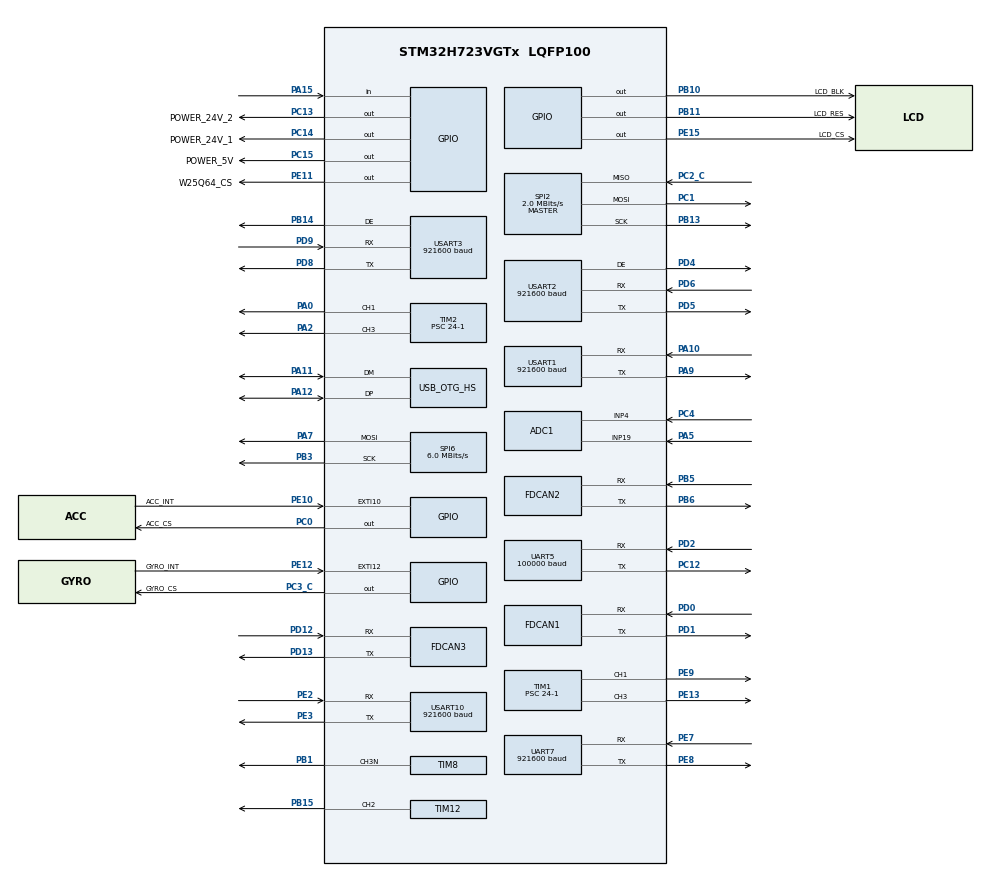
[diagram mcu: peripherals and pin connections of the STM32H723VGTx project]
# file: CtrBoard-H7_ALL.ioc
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ADC1.Channel-0\#ChannelRegularConversion=ADC_CHANNEL_4
ADC1.Channel-1\#ChannelRegularConversion=ADC_CHANNEL_19
ADC1.ClockPrescaler=ADC_CLOCK_ASYNC_DIV64
ADC1.ContinuousConvMode=ENABLE
ADC1.ConversionDataManagement=ADC_CONVERSIONDATA_DMA_CIRCULAR
ADC1.NbrOfConversion=2
ADC1.NbrOfConversionFlag=1
ADC1.OffsetNumber-0\#ChannelRegularConversion=ADC_OFFSET_NONE
ADC1.OffsetNumber-1\#ChannelRegularConversion=ADC_OFFSET_NONE
ADC1.OffsetSignedSaturation-0\#ChannelRegularConversion=DISABLE
ADC1.OffsetSignedSaturation-1\#ChannelRegularConversion=DISABLE
ADC1.Rank-0\#ChannelRegularConversion=1
ADC1.Rank-1\#ChannelRegularConversion=2
ADC1.SamplingTime-0\#ChannelRegularConversion=ADC_SAMPLETIME_32CYCLES_5
ADC1.SamplingTime-1\#ChannelRegularConversion=ADC_SAMPLETIME_32CYCLES_5
ADC1.master=1
Bdma.Request0=SPI6_TX
Bdma.RequestsNb=1
Bdma.SPI6_TX.0.Direction=DMA_MEMORY_TO_PERIPH
Bdma.SPI6_TX.0.EventEnable=DISABLE
Bdma.SPI6_TX.0.Instance=BDMA_Channel0
Bdma.SPI6_TX.0.MemDataAlignment=DMA_MDATAALIGN_BYTE
Bdma.SPI6_TX.0.MemInc=DMA_MINC_ENABLE
Bdma.SPI6_TX.0.Mode=DMA_NORMAL
Bdma.SPI6_TX.0.PeriphDataAlignment=DMA_PDATAALIGN_BYTE
Bdma.SPI6_TX.0.PeriphInc=DMA_PINC_DISABLE
Bdma.SPI6_TX.0.Polarity=HAL_DMAMUX_REQ_GEN_RISING
Bdma.SPI6_TX.0.Priority=DMA_PRIORITY_LOW
Bdma.SPI6_TX.0.RequestNumber=1
Bdma.SPI6_TX.0.SignalID=NONE
Bdma.SPI6_TX.0.SyncEnable=DISABLE
Bdma.SPI6_TX.0.SyncPolarity=HAL_DMAMUX_SYNC_NO_EVENT
Bdma.SPI6_TX.0.SyncRequestNumber=1
Bdma.SPI6_TX.0.SyncSignalID=NONE
CORTEX_M7.CPU_DCache=Enabled
CORTEX_M7.CPU_ICache=Enabled
CORTEX_M7.Enable-Cortex_Memory_Protection_Unit_Region0_Settings=MPU_REGION_ENABLE
CORTEX_M7.MPU_Control=__NULL
CORTEX_M7.default_mode_Activation=1
DAC1.DAC_Channel-DAC_OUT2_Int=DAC_CHANNEL_2
Dma.ADC1.0.Direction=DMA_PERIPH_TO_MEMORY
Dma.ADC1.0.EventEnable=DISABLE
Dma.ADC1.0.FIFOMode=DMA_FIFOMODE_DISABLE
Dma.ADC1.0.Instance=DMA1_Stream0
Dma.ADC1.0.MemDataAlignment=DMA_MDATAALIGN_HALFWORD
Dma.ADC1.0.MemInc=DMA_MINC_ENABLE
Dma.ADC1.0.Mode=DMA_CIRCULAR
Dma.ADC1.0.PeriphDataAlignment=DMA_PDATAALIGN_HALFWORD
Dma.ADC1.0.PeriphInc=DMA_PINC_DISABLE
Dma.ADC1.0.Polarity=HAL_DMAMUX_REQ_GEN_RISING
Dma.ADC1.0.Priority=DMA_PRIORITY_LOW
Dma.ADC1.0.RequestNumber=1
Dma.ADC1.0.SignalID=NONE
Dma.ADC1.0.SyncEnable=DISABLE
Dma.ADC1.0.SyncPolarity=HAL_DMAMUX_SYNC_NO_EVENT
Dma.ADC1.0.SyncRequestNumber=1
Dma.ADC1.0.SyncSignalID=NONE
Dma.Request0=ADC1
Dma.Request1=SPI2_RX
Dma.Request10=USART3_TX
Dma.Request11=USART10_RX
Dma.Request12=USART10_TX
Dma.Request13=UART5_RX
Dma.Request2=SPI2_TX
Dma.Request3=UART7_RX
Dma.Request4=UART7_TX
Dma.Request5=USART1_RX
Dma.Request6=USART1_TX
Dma.Request7=USART2_RX
Dma.Request8=USART2_TX
Dma.Request9=USART3_RX
Dma.SPI2_RX.1.Direction=DMA_PERIPH_TO_MEMORY
Dma.SPI2_RX.1.EventEnable=DISABLE
Dma.SPI2_RX.1.FIFOMode=DMA_FIFOMODE_DISABLE
Dma.SPI2_RX.1.Instance=DMA1_Stream2
Dma.SPI2_RX.1.MemDataAlignment=DMA_MDATAALIGN_BYTE
Dma.SPI2_RX.1.MemInc=DMA_MINC_ENABLE
Dma.SPI2_RX.1.Mode=DMA_NORMAL
Dma.SPI2_RX.1.PeriphDataAlignment=DMA_PDATAALIGN_BYTE
Dma.SPI2_RX.1.PeriphInc=DMA_PINC_DISABLE
Dma.SPI2_RX.1.Polarity=HAL_DMAMUX_REQ_GEN_RISING
Dma.SPI2_RX.1.Priority=DMA_PRIORITY_LOW
Dma.SPI2_RX.1.RequestNumber=1
Dma.SPI2_RX.1.SignalID=NONE
Dma.SPI2_RX.1.SyncEnable=DISABLE
Dma.SPI2_RX.1.SyncPolarity=HAL_DMAMUX_SYNC_NO_EVENT
Dma.SPI2_RX.1.SyncRequestNumber=1
Dma.SPI2_RX.1.SyncSignalID=NONE
Dma.SPI2_TX.2.Direction=DMA_MEMORY_TO_PERIPH
Dma.SPI2_TX.2.EventEnable=DISABLE
Dma.SPI2_TX.2.FIFOMode=DMA_FIFOMODE_DISABLE
Dma.SPI2_TX.2.Instance=DMA1_Stream3
Dma.SPI2_TX.2.MemDataAlignment=DMA_MDATAALIGN_BYTE
Dma.SPI2_TX.2.MemInc=DMA_MINC_ENABLE
Dma.SPI2_TX.2.Mode=DMA_NORMAL
Dma.SPI2_TX.2.PeriphDataAlignment=DMA_PDATAALIGN_BYTE
Dma.SPI2_TX.2.PeriphInc=DMA_PINC_DISABLE
Dma.SPI2_TX.2.Polarity=HAL_DMAMUX_REQ_GEN_RISING
Dma.SPI2_TX.2.Priority=DMA_PRIORITY_LOW
Dma.SPI2_TX.2.RequestNumber=1
Dma.SPI2_TX.2.SignalID=NONE
Dma.SPI2_TX.2.SyncEnable=DISABLE
Dma.SPI2_TX.2.SyncPolarity=HAL_DMAMUX_SYNC_NO_EVENT
Dma.SPI2_TX.2.SyncRequestNumber=1
Dma.SPI2_TX.2.SyncSignalID=NONE
Dma.UART5_RX.13.Direction=DMA_PERIPH_TO_MEMORY
Dma.UART5_RX.13.EventEnable=DISABLE
Dma.UART5_RX.13.FIFOMode=DMA_FIFOMODE_DISABLE
Dma.UART5_RX.13.Instance=DMA1_Stream1
Dma.UART5_RX.13.MemDataAlignment=DMA_MDATAALIGN_BYTE
Dma.UART5_RX.13.MemInc=DMA_MINC_ENABLE
Dma.UART5_RX.13.Mode=DMA_NORMAL
Dma.UART5_RX.13.PeriphDataAlignment=DMA_PDATAALIGN_BYTE
Dma.UART5_RX.13.PeriphInc=DMA_PINC_DISABLE
Dma.UART5_RX.13.Polarity=HAL_DMAMUX_REQ_GEN_RISING
Dma.UART5_RX.13.Priority=DMA_PRIORITY_LOW
Dma.UART5_RX.13.RequestNumber=1
Dma.UART5_RX.13.SignalID=NONE
Dma.UART5_RX.13.SyncEnable=DISABLE
Dma.UART5_RX.13.SyncPolarity=HAL_DMAMUX_SYNC_NO_EVENT
Dma.UART5_RX.13.SyncRequestNumber=1
Dma.UART5_RX.13.SyncSignalID=NONE
Dma.UART7_RX.3.Direction=DMA_PERIPH_TO_MEMORY
Dma.UART7_RX.3.EventEnable=DISABLE
Dma.UART7_RX.3.FIFOMode=DMA_FIFOMODE_DISABLE
Dma.UART7_RX.3.Instance=DMA1_Stream4
Dma.UART7_RX.3.MemDataAlignment=DMA_MDATAALIGN_BYTE
Dma.UART7_RX.3.MemInc=DMA_MINC_ENABLE
Dma.UART7_RX.3.Mode=DMA_NORMAL
Dma.UART7_RX.3.PeriphDataAlignment=DMA_PDATAALIGN_BYTE
Dma.UART7_RX.3.PeriphInc=DMA_PINC_DISABLE
Dma.UART7_RX.3.Polarity=HAL_DMAMUX_REQ_GEN_RISING
Dma.UART7_RX.3.Priority=DMA_PRIORITY_LOW
Dma.UART7_RX.3.RequestNumber=1
Dma.UART7_RX.3.SignalID=NONE
Dma.UART7_RX.3.SyncEnable=DISABLE
Dma.UART7_RX.3.SyncPolarity=HAL_DMAMUX_SYNC_NO_EVENT
Dma.UART7_RX.3.SyncRequestNumber=1
Dma.UART7_RX.3.SyncSignalID=NONE
Dma.UART7_TX.4.Direction=DMA_MEMORY_TO_PERIPH
Dma.UART7_TX.4.EventEnable=DISABLE
Dma.UART7_TX.4.FIFOMode=DMA_FIFOMODE_DISABLE
Dma.UART7_TX.4.Instance=DMA1_Stream5
Dma.UART7_TX.4.MemDataAlignment=DMA_MDATAALIGN_BYTE
Dma.UART7_TX.4.MemInc=DMA_MINC_ENABLE
Dma.UART7_TX.4.Mode=DMA_NORMAL
Dma.UART7_TX.4.PeriphDataAlignment=DMA_PDATAALIGN_BYTE
Dma.UART7_TX.4.PeriphInc=DMA_PINC_DISABLE
Dma.UART7_TX.4.Polarity=HAL_DMAMUX_REQ_GEN_RISING
Dma.UART7_TX.4.Priority=DMA_PRIORITY_LOW
Dma.UART7_TX.4.RequestNumber=1
Dma.UART7_TX.4.SignalID=NONE
Dma.UART7_TX.4.SyncEnable=DISABLE
Dma.UART7_TX.4.SyncPolarity=HAL_DMAMUX_SYNC_NO_EVENT
Dma.UART7_TX.4.SyncRequestNumber=1
Dma.UART7_TX.4.SyncSignalID=NONE
Dma.USART10_RX.11.Direction=DMA_PERIPH_TO_MEMORY
Dma.USART10_RX.11.EventEnable=DISABLE
Dma.USART10_RX.11.FIFOMode=DMA_FIFOMODE_DISABLE
Dma.USART10_RX.11.Instance=DMA2_Stream4
Dma.USART10_RX.11.MemDataAlignment=DMA_MDATAALIGN_BYTE
Dma.USART10_RX.11.MemInc=DMA_MINC_ENABLE
Dma.USART10_RX.11.Mode=DMA_NORMAL
Dma.USART10_RX.11.PeriphDataAlignment=DMA_PDATAALIGN_BYTE
Dma.USART10_RX.11.PeriphInc=DMA_PINC_DISABLE
Dma.USART10_RX.11.Polarity=HAL_DMAMUX_REQ_GEN_RISING
Dma.USART10_RX.11.Priority=DMA_PRIORITY_LOW
Dma.USART10_RX.11.RequestNumber=1
Dma.USART10_RX.11.SignalID=NONE
Dma.USART10_RX.11.SyncEnable=DISABLE
Dma.USART10_RX.11.SyncPolarity=HAL_DMAMUX_SYNC_NO_EVENT
Dma.USART10_RX.11.SyncRequestNumber=1
Dma.USART10_RX.11.SyncSignalID=NONE
Dma.USART10_TX.12.Direction=DMA_MEMORY_TO_PERIPH
Dma.USART10_TX.12.EventEnable=DISABLE
Dma.USART10_TX.12.FIFOMode=DMA_FIFOMODE_DISABLE
Dma.USART10_TX.12.Instance=DMA2_Stream5
Dma.USART10_TX.12.MemDataAlignment=DMA_MDATAALIGN_BYTE
Dma.USART10_TX.12.MemInc=DMA_MINC_ENABLE
Dma.USART10_TX.12.Mode=DMA_NORMAL
Dma.USART10_TX.12.PeriphDataAlignment=DMA_PDATAALIGN_BYTE
Dma.USART10_TX.12.PeriphInc=DMA_PINC_DISABLE
Dma.USART10_TX.12.Polarity=HAL_DMAMUX_REQ_GEN_RISING
Dma.USART10_TX.12.Priority=DMA_PRIORITY_LOW
Dma.USART10_TX.12.RequestNumber=1
Dma.USART10_TX.12.SignalID=NONE
Dma.USART10_TX.12.SyncEnable=DISABLE
Dma.USART10_TX.12.SyncPolarity=HAL_DMAMUX_SYNC_NO_EVENT
Dma.USART10_TX.12.SyncRequestNumber=1
Dma.USART10_TX.12.SyncSignalID=NONE
Dma.USART1_RX.5.Direction=DMA_PERIPH_TO_MEMORY
Dma.USART1_RX.5.EventEnable=DISABLE
Dma.USART1_RX.5.FIFOMode=DMA_FIFOMODE_DISABLE
Dma.USART1_RX.5.Instance=DMA1_Stream6
Dma.USART1_RX.5.MemDataAlignment=DMA_MDATAALIGN_BYTE
Dma.USART1_RX.5.MemInc=DMA_MINC_ENABLE
Dma.USART1_RX.5.Mode=DMA_NORMAL
Dma.USART1_RX.5.PeriphDataAlignment=DMA_PDATAALIGN_BYTE
Dma.USART1_RX.5.PeriphInc=DMA_PINC_DISABLE
Dma.USART1_RX.5.Polarity=HAL_DMAMUX_REQ_GEN_RISING
Dma.USART1_RX.5.Priority=DMA_PRIORITY_LOW
Dma.USART1_RX.5.RequestNumber=1
Dma.USART1_RX.5.SignalID=NONE
Dma.USART1_RX.5.SyncEnable=DISABLE
Dma.USART1_RX.5.SyncPolarity=HAL_DMAMUX_SYNC_NO_EVENT
Dma.USART1_RX.5.SyncRequestNumber=1
Dma.USART1_RX.5.SyncSignalID=NONE
Dma.USART1_TX.6.Direction=DMA_MEMORY_TO_PERIPH
Dma.USART1_TX.6.EventEnable=DISABLE
Dma.USART1_TX.6.FIFOMode=DMA_FIFOMODE_DISABLE
Dma.USART1_TX.6.Instance=DMA1_Stream7
Dma.USART1_TX.6.MemDataAlignment=DMA_MDATAALIGN_BYTE
Dma.USART1_TX.6.MemInc=DMA_MINC_ENABLE
Dma.USART1_TX.6.Mode=DMA_NORMAL
Dma.USART1_TX.6.PeriphDataAlignment=DMA_PDATAALIGN_BYTE
Dma.USART1_TX.6.PeriphInc=DMA_PINC_DISABLE
Dma.USART1_TX.6.Polarity=HAL_DMAMUX_REQ_GEN_RISING
Dma.USART1_TX.6.Priority=DMA_PRIORITY_LOW
Dma.USART1_TX.6.RequestNumber=1
Dma.USART1_TX.6.SignalID=NONE
Dma.USART1_TX.6.SyncEnable=DISABLE
Dma.USART1_TX.6.SyncPolarity=HAL_DMAMUX_SYNC_NO_EVENT
Dma.USART1_TX.6.SyncRequestNumber=1
Dma.USART1_TX.6.SyncSignalID=NONE
Dma.USART2_RX.7.Direction=DMA_PERIPH_TO_MEMORY
Dma.USART2_RX.7.EventEnable=DISABLE
Dma.USART2_RX.7.FIFOMode=DMA_FIFOMODE_DISABLE
Dma.USART2_RX.7.Instance=DMA2_Stream0
Dma.USART2_RX.7.MemDataAlignment=DMA_MDATAALIGN_BYTE
Dma.USART2_RX.7.MemInc=DMA_MINC_ENABLE
Dma.USART2_RX.7.Mode=DMA_NORMAL
Dma.USART2_RX.7.PeriphDataAlignment=DMA_PDATAALIGN_BYTE
Dma.USART2_RX.7.PeriphInc=DMA_PINC_DISABLE
Dma.USART2_RX.7.Polarity=HAL_DMAMUX_REQ_GEN_RISING
Dma.USART2_RX.7.Priority=DMA_PRIORITY_LOW
Dma.USART2_RX.7.RequestNumber=1
Dma.USART2_RX.7.SignalID=NONE
Dma.USART2_RX.7.SyncEnable=DISABLE
Dma.USART2_RX.7.SyncPolarity=HAL_DMAMUX_SYNC_NO_EVENT
Dma.USART2_RX.7.SyncRequestNumber=1
Dma.USART2_RX.7.SyncSignalID=NONE
Dma.USART2_TX.8.Direction=DMA_MEMORY_TO_PERIPH
Dma.USART2_TX.8.EventEnable=DISABLE
Dma.USART2_TX.8.FIFOMode=DMA_FIFOMODE_DISABLE
Dma.USART2_TX.8.Instance=DMA2_Stream1
Dma.USART2_TX.8.MemDataAlignment=DMA_MDATAALIGN_BYTE
Dma.USART2_TX.8.MemInc=DMA_MINC_ENABLE
Dma.USART2_TX.8.Mode=DMA_NORMAL
Dma.USART2_TX.8.PeriphDataAlignment=DMA_PDATAALIGN_BYTE
Dma.USART2_TX.8.PeriphInc=DMA_PINC_DISABLE
Dma.USART2_TX.8.Polarity=HAL_DMAMUX_REQ_GEN_RISING
Dma.USART2_TX.8.Priority=DMA_PRIORITY_LOW
Dma.USART2_TX.8.RequestNumber=1
Dma.USART2_TX.8.SignalID=NONE
Dma.USART2_TX.8.SyncEnable=DISABLE
Dma.USART2_TX.8.SyncPolarity=HAL_DMAMUX_SYNC_NO_EVENT
Dma.USART2_TX.8.SyncRequestNumber=1
Dma.USART2_TX.8.SyncSignalID=NONE
Dma.USART3_RX.9.Direction=DMA_PERIPH_TO_MEMORY
Dma.USART3_RX.9.EventEnable=DISABLE
Dma.USART3_RX.9.FIFOMode=DMA_FIFOMODE_DISABLE
Dma.USART3_RX.9.Instance=DMA2_Stream2
Dma.USART3_RX.9.MemDataAlignment=DMA_MDATAALIGN_BYTE
Dma.USART3_RX.9.MemInc=DMA_MINC_ENABLE
Dma.USART3_RX.9.Mode=DMA_NORMAL
Dma.USART3_RX.9.PeriphDataAlignment=DMA_PDATAALIGN_BYTE
Dma.USART3_RX.9.PeriphInc=DMA_PINC_DISABLE
Dma.USART3_RX.9.Polarity=HAL_DMAMUX_REQ_GEN_RISING
Dma.USART3_RX.9.Priority=DMA_PRIORITY_LOW
Dma.USART3_RX.9.RequestNumber=1
Dma.USART3_RX.9.SignalID=NONE
Dma.USART3_RX.9.SyncEnable=DISABLE
Dma.USART3_RX.9.SyncPolarity=HAL_DMAMUX_SYNC_NO_EVENT
Dma.USART3_RX.9.SyncRequestNumber=1
Dma.USART3_RX.9.SyncSignalID=NONE
Dma.USART3_TX.10.Direction=DMA_MEMORY_TO_PERIPH
Dma.USART3_TX.10.EventEnable=DISABLE
Dma.USART3_TX.10.FIFOMode=DMA_FIFOMODE_DISABLE
Dma.USART3_TX.10.Instance=DMA2_Stream3
Dma.USART3_TX.10.MemDataAlignment=DMA_MDATAALIGN_BYTE
Dma.USART3_TX.10.MemInc=DMA_MINC_ENABLE
Dma.USART3_TX.10.Mode=DMA_NORMAL
Dma.USART3_TX.10.PeriphDataAlignment=DMA_PDATAALIGN_BYTE
Dma.USART3_TX.10.PeriphInc=DMA_PINC_DISABLE
Dma.USART3_TX.10.Polarity=HAL_DMAMUX_REQ_GEN_RISING
Dma.USART3_TX.10.Priority=DMA_PRIORITY_LOW
Dma.USART3_TX.10.RequestNumber=1
Dma.USART3_TX.10.SignalID=NONE
Dma.USART3_TX.10.SyncEnable=DISABLE
Dma.USART3_TX.10.SyncPolarity=HAL_DMAMUX_SYNC_NO_EVENT
Dma.USART3_TX.10.SyncRequestNumber=1
Dma.USART3_TX.10.SyncSignalID=NONE
FDCAN1.CalculateBaudRateNominal=999999
FDCAN1.CalculateTimeBitNominal=1000
FDCAN1.CalculateTimeQuantumNominal=90.90909090909092
FDCAN1.DataPrescaler=1
FDCAN1.DataSyncJumpWidth=10
FDCAN1.DataTimeSeg1=9
FDCAN1.DataTimeSeg2=1
FDCAN1.ExtFiltersNbr=1
FDCAN1.FrameFormat=FDCAN_FRAME_FD_BRS
FDCAN1.MessageRAMOffset=0
FDCAN1.NominalPrescaler=5
FDCAN1.NominalSyncJumpWidth=10
FDCAN1.NominalTimeSeg1=9
FDCAN1.NominalTimeSeg2=1
FDCAN1.RxBufferSize=FDCAN_DATA_BYTES_64
FDCAN1.RxBuffersNbr=0
FDCAN1.RxFifo0ElmtSize=FDCAN_DATA_BYTES_64
FDCAN1.RxFifo0ElmtsNbr=23
FDCAN1.RxFifo1ElmtSize=FDCAN_DATA_BYTES_64
FDCAN1.RxFifo1ElmtsNbr=0
FDCAN1.StdFiltersNbr=1
FDCAN1.TxElmtSize=FDCAN_DATA_BYTES_64
FDCAN1.TxFifoQueueElmtsNbr=23
FDCAN2.CalculateBaudRateNominal=999999
FDCAN2.CalculateTimeBitNominal=1000
FDCAN2.CalculateTimeQuantumNominal=90.90909090909092
FDCAN2.DataPrescaler=1
FDCAN2.DataSyncJumpWidth=10
FDCAN2.DataTimeSeg1=9
FDCAN2.DataTimeSeg2=1
FDCAN2.ExtFiltersNbr=1
FDCAN2.FrameFormat=FDCAN_FRAME_FD_BRS
FDCAN2.MessageRAMOffset=831
FDCAN2.NominalPrescaler=5
FDCAN2.NominalSyncJumpWidth=10
FDCAN2.NominalTimeSeg1=9
FDCAN2.NominalTimeSeg2=1
FDCAN2.RxBufferSize=FDCAN_DATA_BYTES_64
FDCAN2.RxBuffersNbr=0
FDCAN2.RxFifo0ElmtSize=FDCAN_DATA_BYTES_64
FDCAN2.RxFifo0ElmtsNbr=0
FDCAN2.RxFifo1ElmtSize=FDCAN_DATA_BYTES_64
FDCAN2.RxFifo1ElmtsNbr=23
FDCAN2.StdFiltersNbr=1
FDCAN2.TxBuffersNbr=0
FDCAN2.TxElmtSize=FDCAN_DATA_BYTES_64
FDCAN2.TxFifoQueueElmtsNbr=23
FDCAN3.CalculateBaudRateNominal=999999
FDCAN3.CalculateTimeBitNominal=1000
FDCAN3.CalculateTimeQuantumNominal=90.90909090909092
FDCAN3.DataPrescaler=1
FDCAN3.DataSyncJumpWidth=10
FDCAN3.DataTimeSeg1=9
FDCAN3.DataTimeSeg2=1
FDCAN3.ExtFiltersNbr=1
FDCAN3.FrameFormat=FDCAN_FRAME_FD_BRS
FDCAN3.MessageRAMOffset=1662
FDCAN3.Mode=FDCAN_MODE_NORMAL
FDCAN3.NominalPrescaler=5
FDCAN3.NominalSyncJumpWidth=10
FDCAN3.NominalTimeSeg1=9
FDCAN3.NominalTimeSeg2=1
FDCAN3.RxBufferSize=FDCAN_DATA_BYTES_64
FDCAN3.RxBuffersNbr=0
FDCAN3.RxFifo0ElmtSize=FDCAN_DATA_BYTES_64
FDCAN3.RxFifo0ElmtsNbr=0
FDCAN3.RxFifo1ElmtSize=FDCAN_DATA_BYTES_64
FDCAN3.RxFifo1ElmtsNbr=23
FDCAN3.StdFiltersNbr=1
FDCAN3.TxBuffersNbr=0
FDCAN3.TxElmtSize=FDCAN_DATA_BYTES_64
FDCAN3.TxFifoQueueElmtsNbr=23
FREERTOS.INCLUDE_eTaskGetState=1
FREERTOS.INCLUDE_uxTaskGetStackHighWaterMark=1
FREERTOS.INCLUDE_vTaskDelayUntil=1
FREERTOS.INCLUDE_xQueueGetMutexHolder=1
FREERTOS.INCLUDE_xTaskGetCurrentTaskHandle=1
FREERTOS.INCLUDE_xTaskGetSchedulerState=1
FREERTOS.INCLUDE_xTimerPendFunctionCall=0
FREERTOS.Tasks01=defaultTask,48,4096,StartDefaultTask,Default,NULL,Dynamic,NULL,NULL
FREERTOS.configCHECK_FOR_STACK_OVERFLOW=2
FREERTOS.configENABLE_BACKWARD_COMPATIBILITY=0
FREERTOS.configENABLE_FPU=1
FREERTOS.configRECORD_STACK_HIGH_ADDRESS=1
FREERTOS.configTOTAL_HEAP_SIZE=0x18800
FREERTOS.configUSE_COUNTING_SEMAPHORES=1
FREERTOS.configUSE_RECURSIVE_MUTEXES=1
FREERTOS.configUSE_TASK_NOTIFICATIONS=1
FREERTOS.configUSE_TIMERS=0
FREERTOS.configUSE_TRACE_FACILITY=1
Mcu.Family=STM32H7
Mcu.Name=STM32H723VGTx
Mcu.Package=LQFP100
NVIC.BDMA_Channel0_IRQn=true\:5\:0\:false\:false\:true\:true\:false\:true\:true
NVIC.DMA1_Stream0_IRQn=true\:5\:0\:false\:false\:true\:false\:false\:true\:true
NVIC.DMA1_Stream1_IRQn=true\:5\:0\:false\:false\:true\:true\:false\:true\:true
NVIC.DMA1_Stream2_IRQn=true\:5\:0\:false\:false\:true\:true\:false\:true\:true
NVIC.DMA1_Stream3_IRQn=true\:5\:0\:false\:false\:true\:true\:false\:true\:true
NVIC.DMA1_Stream4_IRQn=true\:5\:0\:false\:false\:true\:true\:false\:true\:true
NVIC.DMA1_Stream5_IRQn=true\:5\:0\:false\:false\:true\:true\:false\:true\:true
NVIC.DMA1_Stream6_IRQn=true\:5\:0\:false\:false\:true\:true\:false\:true\:true
NVIC.DMA1_Stream7_IRQn=true\:5\:0\:false\:false\:true\:true\:false\:true\:true
NVIC.DMA2_Stream0_IRQn=true\:5\:0\:false\:false\:true\:true\:false\:true\:true
NVIC.DMA2_Stream1_IRQn=true\:5\:0\:false\:false\:true\:true\:false\:true\:true
NVIC.DMA2_Stream2_IRQn=true\:5\:0\:false\:false\:true\:true\:false\:true\:true
NVIC.DMA2_Stream3_IRQn=true\:5\:0\:false\:false\:true\:true\:false\:true\:true
NVIC.DMA2_Stream4_IRQn=true\:5\:0\:false\:false\:true\:true\:false\:true\:true
NVIC.DMA2_Stream5_IRQn=true\:5\:0\:false\:false\:true\:true\:false\:true\:true
NVIC.EXTI15_10_IRQn=true\:5\:0\:true\:false\:true\:true\:true\:true\:true
NVIC.FDCAN1_IT0_IRQn=true\:5\:0\:false\:false\:true\:true\:true\:true\:true
NVIC.FDCAN1_IT1_IRQn=true\:5\:0\:false\:false\:true\:true\:true\:true\:true
NVIC.FDCAN2_IT0_IRQn=true\:5\:0\:false\:false\:true\:true\:true\:true\:true
NVIC.FDCAN2_IT1_IRQn=true\:5\:0\:false\:false\:true\:true\:true\:true\:true
NVIC.FDCAN3_IT0_IRQn=true\:5\:0\:false\:false\:true\:true\:true\:true\:true
NVIC.FDCAN3_IT1_IRQn=true\:5\:0\:false\:false\:true\:true\:true\:true\:true
NVIC.OTG_HS_IRQn=true\:5\:0\:false\:false\:true\:true\:true\:true\:true
NVIC.PriorityGroup=NVIC_PRIORITYGROUP_4
NVIC.SPI2_IRQn=true\:5\:0\:false\:false\:true\:true\:false\:true\:true
NVIC.SPI6_IRQn=true\:5\:0\:false\:false\:true\:true\:true\:true\:true
NVIC.TIM4_IRQn=true\:0\:0\:false\:false\:true\:false\:false\:true\:true
NVIC.TimeBase=TIM4_IRQn
NVIC.TimeBaseIP=TIM4
NVIC.UART5_IRQn=true\:5\:0\:false\:false\:true\:true\:true\:true\:true
NVIC.UART7_IRQn=true\:5\:0\:true\:false\:true\:false\:true\:true\:true
NVIC.USART10_IRQn=true\:5\:0\:true\:false\:true\:false\:true\:true\:true
NVIC.USART1_IRQn=true\:5\:0\:true\:false\:true\:false\:true\:true\:true
NVIC.USART2_IRQn=true\:5\:0\:true\:false\:true\:false\:true\:true\:true
NVIC.USART3_IRQn=true\:5\:0\:true\:false\:true\:false\:true\:true\:true
PA0.Signal=S_TIM2_CH1_ETR
PA10.Mode=Asynchronous
PA10.Signal=USART1_RX
PA11.Mode=Device_Only_FS
PA11.Signal=USB_OTG_HS_DM
PA12.Mode=Device_Only_FS
PA12.Signal=USB_OTG_HS_DP
PA13(JTMS/SWDIO).Mode=Serial_Wire
PA13(JTMS/SWDIO).Signal=DEBUG_JTMS-SWDIO
PA14(JTCK/SWCLK).Mode=Serial_Wire
PA14(JTCK/SWCLK).Signal=DEBUG_JTCK-SWCLK
PA15(JTDI).Signal=GPIO_Input
PA2.Signal=S_TIM2_CH3
PA5.Signal=ADCx_INP19
PA7.Mode=TX_Only_Simplex_Unidirect_Master
PA7.Signal=SPI6_MOSI
PA9.Mode=Asynchronous
PA9.Signal=USART1_TX
PB1.Mode=PWM Generation3 CH3N
PB1.Signal=TIM8_CH3N
PB10.GPIO_Label=LCD_BLK
PB10.Signal=GPIO_Output
PB11.GPIO_Label=LCD_RES
PB11.Signal=GPIO_Output
PB13.GPIO_Speed=GPIO_SPEED_FREQ_VERY_HIGH
PB13.Mode=Full_Duplex_Master
PB13.Signal=SPI2_SCK
PB14.Mode=Hardware Flow Control (RS485)
PB14.Signal=USART3_DE
PB15.Signal=S_TIM12_CH2
PB3(JTDO/TRACESWO).Mode=TX_Only_Simplex_Unidirect_Master
PB3(JTDO/TRACESWO).Signal=SPI6_SCK
PB5.Mode=FDCAN_Activate
PB5.Signal=FDCAN2_RX
PB6.Mode=FDCAN_Activate
PB6.Signal=FDCAN2_TX
PC0.GPIO_Label=ACC_CS
PC0.GPIO_Speed=GPIO_SPEED_FREQ_VERY_HIGH
PC0.PinState=GPIO_PIN_SET
PC0.Signal=GPIO_Output
PC1.GPIO_Speed=GPIO_SPEED_FREQ_VERY_HIGH
PC1.Mode=Full_Duplex_Master
PC1.Signal=SPI2_MOSI
PC12.Mode=Asynchronous
PC12.Signal=UART5_TX
PC13.GPIO_Label=POWER_24V_2
PC13.PinState=GPIO_PIN_SET
PC13.Signal=GPIO_Output
PC14-OSC32_IN.GPIO_Label=POWER_24V_1
PC14-OSC32_IN.PinState=GPIO_PIN_SET
PC14-OSC32_IN.Signal=GPIO_Output
PC15-OSC32_OUT.GPIO_Label=POWER_5V
PC15-OSC32_OUT.PinState=GPIO_PIN_SET
PC15-OSC32_OUT.Signal=GPIO_Output
PC2_C.GPIO_Speed=GPIO_SPEED_FREQ_VERY_HIGH
PC2_C.Mode=Full_Duplex_Master
PC2_C.Signal=SPI2_MISO
PC3_C.GPIO_Label=GYRO_CS
PC3_C.GPIO_Speed=GPIO_SPEED_FREQ_VERY_HIGH
PC3_C.PinState=GPIO_PIN_SET
PC3_C.Signal=GPIO_Output
PC4.Signal=ADCx_INP4
PD0.Mode=FDCAN_Activate
PD0.Signal=FDCAN1_RX
PD1.Mode=FDCAN_Activate
PD1.Signal=FDCAN1_TX
PD12.Mode=FDCAN_Activate
PD12.Signal=FDCAN3_RX
PD13.Mode=FDCAN_Activate
PD13.Signal=FDCAN3_TX
PD2.Mode=Asynchronous
PD2.Signal=UART5_RX
PD4.Mode=Hardware Flow Control (RS485)
PD4.Signal=USART2_DE
PD5.Mode=Asynchronous
PD5.Signal=USART2_TX
PD6.Mode=Asynchronous
PD6.Signal=USART2_RX
PD8.Mode=Asynchronous
PD8.Signal=USART3_TX
PD9.Mode=Asynchronous
PD9.Signal=USART3_RX
PE10.GPIO_Label=ACC_INT
PE10.GPIO_PuPd=GPIO_NOPULL
PE10.Signal=GPXTI10
PE11.GPIO_Label=W25Q64_CS
PE11.Signal=GPIO_Output
PE12.GPIO_Label=GYRO_INT
PE12.Signal=GPXTI12
PE13.Signal=S_TIM1_CH3
PE15.GPIO_Label=LCD_CS
PE15.Signal=GPIO_Output
PE2.Mode=Asynchronous
PE2.Signal=USART10_RX
PE3.Mode=Asynchronous
PE3.Signal=USART10_TX
PE7.Mode=Asynchronous
PE7.Signal=UART7_RX
PE8.Mode=Asynchronous
PE8.Signal=UART7_TX
PE9.Signal=S_TIM1_CH1
PH0-OSC_IN.Mode=HSE-External-Oscillator
PH0-OSC_IN.Signal=RCC_OSC_IN
PH1-OSC_OUT.Mode=HSE-External-Oscillator
PH1-OSC_OUT.Signal=RCC_OSC_OUT
ProjectManager.HeapSize=0x200
ProjectManager.StackSize=0x800
ProjectManager.TargetToolchain=CMake
RCC.ADCFreq_Value=64000000
RCC.APB1Freq_Value=137500000
RCC.APB2Freq_Value=137500000
RCC.APB3Freq_Value=137500000
RCC.APB4Freq_Value=137500000
RCC.CortexFreq_Value=550000000
RCC.D1PPRE=RCC_APB3_DIV2
RCC.D2PPRE1=RCC_APB1_DIV2
RCC.D2PPRE2=RCC_APB2_DIV2
RCC.D3PPRE=RCC_APB4_DIV2
RCC.DIVM1=3
RCC.DIVM2=2
RCC.DIVN1=68
RCC.DIVN2=16
RCC.DIVN3=128
RCC.DIVP1=1
RCC.DIVP2=3
RCC.DIVP3=4
RCC.DIVQ1=10
RCC.HCLKFreq_Value=275000000
RCC.HPRE=RCC_HCLK_DIV2
RCC.HSE_VALUE=24000000
RCC.PLL2FRACN=0
RCC.PLL2_VCI_Range-AdvancedSettings=RCC_PLL2VCIRANGE_0
RCC.PLL2_VCO_SEL-AdvancedSettings=RCC_PLL2VCOWIDE
RCC.PLL3FRACN=0
RCC.PLL3_VCO_SEL-AdvancedSettings=RCC_PLL3VCOMEDIUM
RCC.PLLFRACN=6144
RCC.PLLSourceVirtual=RCC_PLLSOURCE_HSE
RCC.SPI123CLockSelection=RCC_SPI123CLKSOURCE_PLL2
RCC.SPI6CLockSelection=RCC_SPI6CLKSOURCE_HSE
RCC.SYSCLKFreq_VALUE=550000000
RCC.SYSCLKSource=RCC_SYSCLKSOURCE_PLLCLK
RCC.USBCLockSelection=RCC_USBCLKSOURCE_HSI48
RCC.USBFreq_Value=48000000
SH.ADCx_INP19.0=ADC1_INP19,IN19-Single-Ended
SH.ADCx_INP4.0=ADC1_INP4,IN4-Single-Ended
SH.S_TIM12_CH2.0=TIM12_CH2,PWM Generation2 CH2
SH.S_TIM1_CH1.0=TIM1_CH1,PWM Generation1 CH1
SH.S_TIM1_CH3.0=TIM1_CH3,PWM Generation3 CH3
SH.S_TIM2_CH1_ETR.0=TIM2_CH1,PWM Generation1 CH1
SH.S_TIM2_CH3.0=TIM2_CH3,PWM Generation3 CH3
SPI2.BaudRatePrescaler=SPI_BAUDRATEPRESCALER_32
SPI2.CLKPhase=SPI_PHASE_2EDGE
SPI2.CLKPolarity=SPI_POLARITY_HIGH
SPI2.CalculateBaudRate=2.0 MBits/s
SPI2.DataSize=SPI_DATASIZE_8BIT
SPI2.Direction=SPI_DIRECTION_2LINES
SPI2.Mode=SPI_MODE_MASTER
SPI2.VirtualType=VM_MASTER
SPI6.BaudRatePrescaler=SPI_BAUDRATEPRESCALER_4
SPI6.CLKPhase=SPI_PHASE_2EDGE
SPI6.CalculateBaudRate=6.0 MBits/s
SPI6.DataSize=SPI_DATASIZE_8BIT
SPI6.Direction=SPI_DIRECTION_2LINES_TXONLY
SPI6.Mode=SPI_MODE_MASTER
SPI6.VirtualType=VM_MASTER
TIM1.Channel-PWM\ Generation1\ CH1=TIM_CHANNEL_1
TIM1.Channel-PWM\ Generation3\ CH3=TIM_CHANNEL_3
TIM1.Period=10000-1
TIM1.Prescaler=24-1
TIM1.Pulse-PWM\ Generation1\ CH1=5000
TIM1.Pulse-PWM\ Generation3\ CH3=5000
TIM12.Channel-PWM\ Generation2\ CH2=TIM_CHANNEL_2
TIM12.Period=2000-1
TIM12.Prescaler=24-1
TIM2.Channel-PWM\ Generation1\ CH1=TIM_CHANNEL_1
TIM2.Channel-PWM\ Generation3\ CH3=TIM_CHANNEL_3
TIM2.Period=10000-1
TIM2.Prescaler=24-1
TIM2.Pulse-PWM\ Generation1\ CH1=5000
TIM2.Pulse-PWM\ Generation3\ CH3=5000
TIM8.AutoReloadPreload=TIM_AUTORELOAD_PRELOAD_ENABLE
TIM8.Channel-PWM\ Generation3\ CH3N=TIM_CHANNEL_3
TIM8.OffStateIDLEMode=TIM_OSSI_ENABLE
TIM8.Period=10000-1
TIM8.Prescaler=24-1
UART5.BaudRate=100000
UART5.Mode=MODE_RX
UART5.Parity=PARITY_EVEN
UART5.WordLength=WORDLENGTH_9B
UART7.BaudRate=921600
USART1.BaudRate=921600
USART1.VirtualMode-Asynchronous=VM_ASYNC
USART10.BaudRate=921600
USART10.VirtualMode=VM_ASYNC
USART2.BaudRate=921600
USART2.VirtualMode-Asynchronous=VM_ASYNC
USART2.VirtualMode-Hardware\ Flow\ Control\ (RS485)=VM_ASYNC
USART3.BaudRate=921600
USART3.VirtualMode-Asynchronous=VM_ASYNC
USART3.VirtualMode-Hardware\ Flow\ Control\ (RS485)=VM_ASYNC
USB_OTG_HS.VirtualMode-Device_Only_FS=Device_Only_FS
USB_OTG_HS.dma_enable-Device_Only_FS=ENABLE
VP_DAC1_VS_DACI2.Mode=DAC_OUT2_Int
VP_FREERTOS_VS_CMSIS_V2.Mode=CMSIS_V2
VP_MEMORYMAP_VS_MEMORYMAP.Mode=CurAppReg
VP_SYS_VS_tim4.Mode=TIM4
board=custom

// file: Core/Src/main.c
/* USER CODE BEGIN Header */
/**
  ******************************************************************************
  * @file           : main.c
  * @brief          : Main program body
  ******************************************************************************
  * @attention
  *
  * Copyright (c) 2025 STMicroelectronics.
  * All rights reserved.
  *
  * This software is licensed under terms that can be found in the LICENSE file
  * in the root directory of this software component.
  * If no LICENSE file comes with this software, it is provided AS-IS.
  *
  ******************************************************************************
  */
/* USER CODE END Header */
#include "main.h"
#include "FreeRTOS.h"
#include "cmsis_os2.h"
#include "adc.h"
#include "bdma.h"
#include "dac.h"
#include "dma.h"
#include "fdcan.h"
#include "spi.h"
#include "tim.h"
#include "usart.h"
#include "usb_otg.h"
#include "gpio.h"

void SystemClock_Config(void);
void PeriphCommonClock_Config(void);
void MX_FREERTOS_Init(void);

int main(void)
{

  /* Enable the CPU Cache */

  /* Enable I-Cache---------------------------------------------------------*/
  SCB_EnableICache();

  /* Enable D-Cache---------------------------------------------------------*/
  SCB_EnableDCache();

  /* MCU Configuration--------------------------------------------------------*/

  /* Reset of all peripherals, Initializes the Flash interface and the Systick. */
  HAL_Init();

  /* Configure the system clock */
  SystemClock_Config();

  /* Configure the peripherals common clocks */
  PeriphCommonClock_Config();

  /* Initialize all configured peripherals */
  MX_GPIO_Init();
  MX_DMA_Init();
  MX_BDMA_Init();
  MX_ADC1_Init();
  MX_TIM12_Init();
  MX_SPI6_Init();
  MX_SPI2_Init();
  MX_TIM8_Init();
  MX_USART1_UART_Init();
  MX_USART2_UART_Init();
  MX_USART3_UART_Init();
  MX_UART7_Init();
  MX_USART10_UART_Init();
  MX_FDCAN1_Init();
  MX_FDCAN2_Init();
  MX_FDCAN3_Init();
  MX_TIM1_Init();
  MX_TIM2_Init();
  MX_DAC1_Init();
  MX_USB_OTG_HS_PCD_Init();
  MX_UART5_Init();

  /* Init scheduler */
  osKernelInitialize();  /* Call init function for freertos objects (in cmsis_os2.c) */
  MX_FREERTOS_Init();

  /* Start scheduler */
  osKernelStart();

  /* We should never get here as control is now taken by the scheduler */

  /* Infinite loop */
  while (1)
  {

  }
}

void SystemClock_Config(void)
{
  RCC_OscInitTypeDef RCC_OscInitStruct = {0};
  RCC_ClkInitTypeDef RCC_ClkInitStruct = {0};

  /** Supply configuration update enable
  */
  HAL_PWREx_ConfigSupply(PWR_LDO_SUPPLY);

  /** Configure the main internal regulator output voltage
  */
  __HAL_PWR_VOLTAGESCALING_CONFIG(PWR_REGULATOR_VOLTAGE_SCALE0);

  while(!__HAL_PWR_GET_FLAG(PWR_FLAG_VOSRDY)) {}

  /** Initializes the RCC Oscillators according to the specified parameters
  * in the RCC_OscInitTypeDef structure.
  */
  RCC_OscInitStruct.OscillatorType = RCC_OSCILLATORTYPE_HSI48|RCC_OSCILLATORTYPE_HSE;
  RCC_OscInitStruct.HSEState = RCC_HSE_ON;
  RCC_OscInitStruct.HSI48State = RCC_HSI48_ON;
  RCC_OscInitStruct.PLL.PLLState = RCC_PLL_ON;
  RCC_OscInitStruct.PLL.PLLSource = RCC_PLLSOURCE_HSE;
  RCC_OscInitStruct.PLL.PLLM = 3;
  RCC_OscInitStruct.PLL.PLLN = 68;
  RCC_OscInitStruct.PLL.PLLP = 1;
  RCC_OscInitStruct.PLL.PLLQ = 10;
  RCC_OscInitStruct.PLL.PLLR = 2;
  RCC_OscInitStruct.PLL.PLLRGE = RCC_PLL1VCIRANGE_3;
  RCC_OscInitStruct.PLL.PLLVCOSEL = RCC_PLL1VCOWIDE;
  RCC_OscInitStruct.PLL.PLLFRACN = 6144;
  if (HAL_RCC_OscConfig(&RCC_OscInitStruct) != HAL_OK)
  {
    Error_Handler();
  }

  /** Initializes the CPU, AHB and APB buses clocks
  */
  RCC_ClkInitStruct.ClockType = RCC_CLOCKTYPE_HCLK|RCC_CLOCKTYPE_SYSCLK
                              |RCC_CLOCKTYPE_PCLK1|RCC_CLOCKTYPE_PCLK2
                              |RCC_CLOCKTYPE_D3PCLK1|RCC_CLOCKTYPE_D1PCLK1;
  RCC_ClkInitStruct.SYSCLKSource = RCC_SYSCLKSOURCE_PLLCLK;
  RCC_ClkInitStruct.SYSCLKDivider = RCC_SYSCLK_DIV1;
  RCC_ClkInitStruct.AHBCLKDivider = RCC_HCLK_DIV2;
  RCC_ClkInitStruct.APB3CLKDivider = RCC_APB3_DIV2;
  RCC_ClkInitStruct.APB1CLKDivider = RCC_APB1_DIV2;
  RCC_ClkInitStruct.APB2CLKDivider = RCC_APB2_DIV2;
  RCC_ClkInitStruct.APB4CLKDivider = RCC_APB4_DIV2;

  if (HAL_RCC_ClockConfig(&RCC_ClkInitStruct, FLASH_LATENCY_3) != HAL_OK)
  {
    Error_Handler();
  }
}

void PeriphCommonClock_Config(void)
{
  RCC_PeriphCLKInitTypeDef PeriphClkInitStruct = {0};

  /** Initializes the peripherals clock
  */
  PeriphClkInitStruct.PeriphClockSelection = RCC_PERIPHCLK_ADC|RCC_PERIPHCLK_SPI2;
  PeriphClkInitStruct.PLL2.PLL2M = 2;
  PeriphClkInitStruct.PLL2.PLL2N = 16;
  PeriphClkInitStruct.PLL2.PLL2P = 3;
  PeriphClkInitStruct.PLL2.PLL2Q = 2;
  PeriphClkInitStruct.PLL2.PLL2R = 2;
  PeriphClkInitStruct.PLL2.PLL2RGE = RCC_PLL2VCIRANGE_3;
  PeriphClkInitStruct.PLL2.PLL2VCOSEL = RCC_PLL2VCOWIDE;
  PeriphClkInitStruct.PLL2.PLL2FRACN = 0;
  PeriphClkInitStruct.Spi123ClockSelection = RCC_SPI123CLKSOURCE_PLL2;
  PeriphClkInitStruct.AdcClockSelection = RCC_ADCCLKSOURCE_PLL2;
  if (HAL_RCCEx_PeriphCLKConfig(&PeriphClkInitStruct) != HAL_OK)
  {
    Error_Handler();
  }
}

void HAL_TIM_PeriodElapsedCallback(TIM_HandleTypeDef *htim)
{
  if (htim->Instance == TIM4)
  {
    HAL_IncTick();
  }
}

void Error_Handler(void)
{
  /* USER CODE BEGIN Error_Handler_Debug */
  /* User can add his own implementation to report the HAL error return state */
  TIM8->BDTR &= ~TIM_BDTR_MOE;
  __disable_irq();
  while (1)
  {
  }
  /* USER CODE END Error_Handler_Debug */
}

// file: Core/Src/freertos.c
/* USER CODE BEGIN Header */
/**
 ******************************************************************************
 * File Name          : freertos.c
 * Description        : Code for freertos applications
 ******************************************************************************
 * @attention
 *
 * Copyright (c) 2025 STMicroelectronics.
 * All rights reserved.
 *
 * This software is licensed under terms that can be found in the LICENSE file
 * in the root directory of this software component.
 * If no LICENSE file comes with this software, it is provided AS-IS.
 *
 ******************************************************************************
 */
/* USER CODE END Header */

#include "FreeRTOS.h"
#include "task.h"
#include "main.h"
#include "FreeRTOS.h"
#include "cmsis_os2.h"

/* USER CODE BEGIN Includes */
#include <stdbool.h>

#include "app_main.h"
/* USER CODE END Includes */

/* Definitions for defaultTask */
osThreadId_t defaultTaskHandle;
const osThreadAttr_t defaultTask_attributes = {
  .name = "defaultTask",
  .stack_size = 4096 * 4,
  .priority = (osPriority_t) osPriorityRealtime,
};

void StartDefaultTask(void *argument);

void MX_FREERTOS_Init(void); /* (MISRA C 2004 rule 8.1) */

/* Hook prototypes */
void vApplicationStackOverflowHook(TaskHandle_t xTask, char *pcTaskName);

/* USER CODE BEGIN 4 */
/* 栈溢出时进入 LibXR 的错误处理；强定义覆盖 CubeMX、CMSIS-RTOS2 和 LibXR 中的弱定义。
   A stack overflow goes to LibXR's error handling; this strong definition overrides the weak
   ones of CubeMX, CMSIS-RTOS2 and LibXR. */
extern void libxr_fatal_error(const char *file, uint32_t line, bool in_isr);

void vApplicationStackOverflowHook(TaskHandle_t xTask, char *pcTaskName)
{
  (void)xTask;
  (void)pcTaskName;
  taskDISABLE_INTERRUPTS();
  libxr_fatal_error(__FILE__, __LINE__, false);
}
/* USER CODE END 4 */

void MX_FREERTOS_Init(void) {

  /* Create the thread(s) */
  /* creation of defaultTask */
  defaultTaskHandle = osThreadNew(StartDefaultTask, NULL, &defaultTask_attributes);

}

void StartDefaultTask(void *argument)
{
  /* USER CODE BEGIN StartDefaultTask */
  app_main();
  /* Infinite loop */
  for (;;) {
    osDelay(1);
  }
  /* USER CODE END StartDefaultTask */
}
